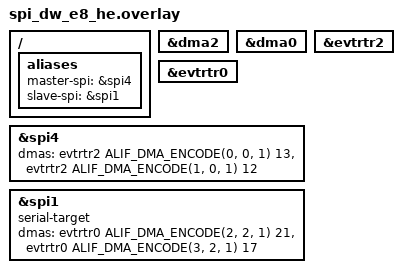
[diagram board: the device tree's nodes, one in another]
/* Copyright (C) 2026 Alif Semiconductor - All Rights Reserved.
 * Use, distribution and modification of this code is permitted under the
 * terms stated in the Alif Semiconductor Software License Agreement
 *
 * You should have received a copy of the Alif Semiconductor Software
 * License Agreement with this file. If not, please write to:
 * contact@alifsemi.com, or visit: https://alifsemi.com/license
 *
 */

/*
 * E8 HE: SPI4 (master) + SPI1 (slave), DMA2 + DMA0, evtrtr2 + evtrtr0.
 * PM: MRAM boot SOFT_OFF (HE, RTC wakeup).
 */

#include "pm_mram_he.overlay"

#include <zephyr/dt-bindings/dma/alif_dma_event_router.h>

/ {
	aliases {
		master-spi = &spi4;
		slave-spi = &spi1;
	};
};

&dma2 {
	status = "okay";
};

&dma0 {
	status = "okay";
};

&evtrtr2 {
	status = "okay";
};

&evtrtr0 {
	status = "okay";
};

&spi4 {
	status = "okay";
	dmas = <&evtrtr2 ALIF_DMA_ENCODE(0, 0, 1) 13>,
	       <&evtrtr2 ALIF_DMA_ENCODE(1, 0, 1) 12>;
	dma-names = "txdma", "rxdma";
};

&spi1 {
	status = "okay";
	serial-target;
	dmas = <&evtrtr0 ALIF_DMA_ENCODE(2, 2, 1) 21>,
	       <&evtrtr0 ALIF_DMA_ENCODE(3, 2, 1) 17>;
	dma-names = "txdma", "rxdma";
};
